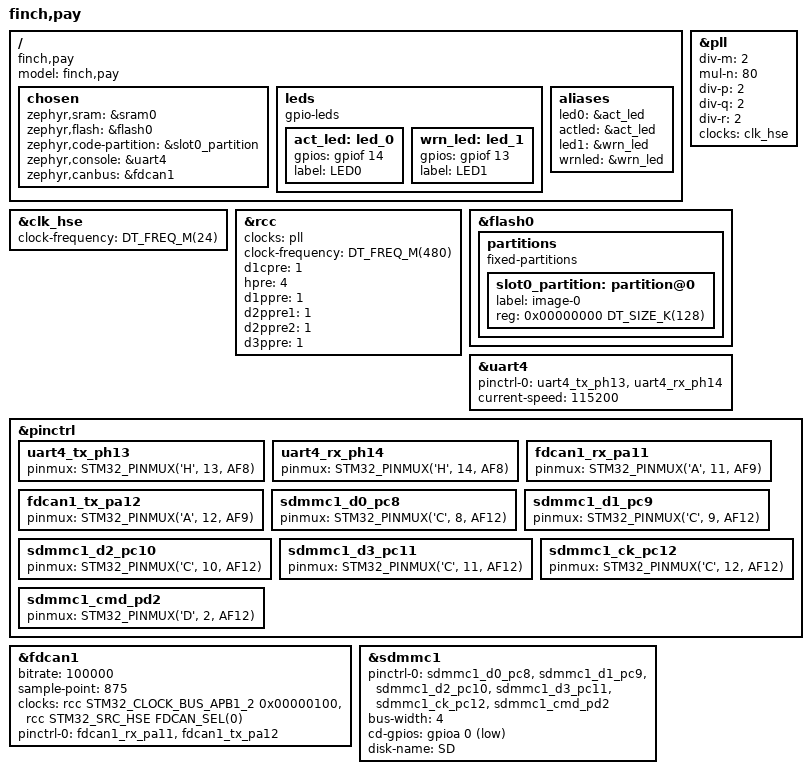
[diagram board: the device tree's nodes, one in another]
/*
 * Copyright (c) 2025 The FINCH CubeSat Project Flight Software Contributors
 *
 * SPDX-License-Identifier: Apache-2.0
 */

/dts-v1/;

#include <st/h7/stm32h743Xi.dtsi>
#include <zephyr/dt-bindings/pinctrl/stm32-pinctrl.h>
#include <zephyr/dt-bindings/clock/stm32h7_clock.h>

/ {
	model = "finch,pay";
	compatible = "finch,pay";

	chosen {
		zephyr,sram = &sram0;
		zephyr,flash = &flash0;
		zephyr,code-partition = &slot0_partition;
		zephyr,console = &uart4;
		zephyr,canbus = &fdcan1;
	};

	leds: leds {
		compatible = "gpio-leds";
		act_led: led_0 {
			gpios = <&gpiof 14 GPIO_ACTIVE_HIGH>;
			label = "LED0";
		};
		wrn_led: led_1 {
			gpios = <&gpiof 13 GPIO_ACTIVE_HIGH>;
			label = "LED1";
		};
	};

	aliases {
		led0 = &act_led;
		actled = &act_led;
		led1 = &wrn_led;
		wrnled = &wrn_led;
	};
};

&clk_hse {
	clock-frequency = <DT_FREQ_M(24)>;
	status = "okay";
};

&pll {
	div-m = <2>;
	mul-n = <80>;
	div-p = <2>;
	div-q = <2>;
	div-r = <2>;
	clocks = <&clk_hse>;
	status = "okay";
};

&rcc {
	clocks = <&pll>;
	clock-frequency = <DT_FREQ_M(480)>;
	d1cpre = <1>;
	hpre = <4>;
	d1ppre = <1>;
	d2ppre1 = <1>;
	d2ppre2 = <1>;
	d3ppre = <1>;
};

&flash0 {
	partitions {
		compatible = "fixed-partitions";
		#address-cells = <1>;
		#size-cells = <1>;
		slot0_partition: partition@0 {
			label = "image-0";
			reg = <0x00000000 DT_SIZE_K(128)>;
		};
	};
};

&uart4 {
	pinctrl-0 = <&uart4_tx_ph13 &uart4_rx_ph14>;
	pinctrl-names = "default";
	current-speed = <115200>;
	status = "okay";
};

&pinctrl {
	uart4_tx_ph13: uart4_tx_ph13 {
		pinmux = <STM32_PINMUX('H', 13, AF8)>;
	};

	uart4_rx_ph14: uart4_rx_ph14 {
		pinmux = <STM32_PINMUX('H', 14, AF8)>;
	};

	fdcan1_rx_pa11: fdcan1_rx_pa11 {
		pinmux = <STM32_PINMUX('A', 11, AF9)>;
	};

	fdcan1_tx_pa12: fdcan1_tx_pa12 {
		pinmux = <STM32_PINMUX('A', 12, AF9)>;
	};
};

&fdcan1 {
	bitrate = <100000>;
	sample-point = <875>;
	clocks = <&rcc STM32_CLOCK_BUS_APB1_2 0x00000100>,
			<&rcc STM32_SRC_HSE FDCAN_SEL(0)>;

	pinctrl-0 = <&fdcan1_rx_pa11 &fdcan1_tx_pa12>;
	pinctrl-names = "default";

	status = "okay";
};

&pinctrl {
    sdmmc1_d0_pc8: sdmmc1_d0_pc8 {
        pinmux = <STM32_PINMUX('C', 8, AF12)>;
    };

    sdmmc1_d1_pc9: sdmmc1_d1_pc9 {
        pinmux = <STM32_PINMUX('C', 9, AF12)>;
    };

    sdmmc1_d2_pc10: sdmmc1_d2_pc10 {
        pinmux = <STM32_PINMUX('C', 10, AF12)>;
    };

    sdmmc1_d3_pc11: sdmmc1_d3_pc11 {
        pinmux = <STM32_PINMUX('C', 11, AF12)>;
    };

    sdmmc1_ck_pc12: sdmmc1_ck_pc12 {
        pinmux = <STM32_PINMUX('C', 12, AF12)>;
    };

    sdmmc1_cmd_pd2: sdmmc1_cmd_pd2 {
        pinmux = <STM32_PINMUX('D', 2, AF12)>;
    };
};

&sdmmc1 {
    status = "okay";

    pinctrl-0 = <
        &sdmmc1_d0_pc8
        &sdmmc1_d1_pc9
        &sdmmc1_d2_pc10
        &sdmmc1_d3_pc11
        &sdmmc1_ck_pc12
        &sdmmc1_cmd_pd2
    >;

    pinctrl-names = "default";

    bus-width = <4>;

    cd-gpios = <&gpioa 0 GPIO_ACTIVE_LOW>;

    disk-name = "SD";
};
